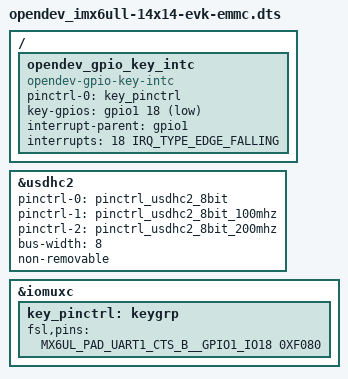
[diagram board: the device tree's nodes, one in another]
/*
 * Copyright 2019 NXP
 *
 * This program is free software; you can redistribute it and/or
 * modify it under the terms of the GNU General Public License
 * as published by the Free Software Foundation; either version 2
 * of the License, or (at your option) any later version.
 */

#include "imx6ull-14x14-evk.dts"

&usdhc2 {
	pinctrl-names = "default", "state_100mhz", "state_200mhz";
	pinctrl-0 = <&pinctrl_usdhc2_8bit>;
	pinctrl-1 = <&pinctrl_usdhc2_8bit_100mhz>;
	pinctrl-2 = <&pinctrl_usdhc2_8bit_200mhz>;
	bus-width = <8>;
	non-removable;
	status = "okay";
};

// &iomuxc {
// 	pinctrl_test: testgrp {
// 		fsl,pins = <
// 		MX6UL_PAD_GPIO1_IO00__GPIO1_IO00 config /* config 是具体设置的值 */
// 		>;
// 	};
// };

// 使用 pinctrl 和 GPIO 子系统的方式
&iomuxc {
    key_pinctrl: keygrp {
        fsl,pins = <
			MX6UL_PAD_UART1_CTS_B__GPIO1_IO18 0XF080 /* GPIO1_IO18 KEY0 */
        >;
    };
};

// 创建 GPIO 节点
/ {
    opendev_gpio_key_intc {
		#address-cells = <1>;
		#size-cells = <1>;
        compatible = "opendev-gpio-key-intc";
        pinctrl-names = "default";
		pinctrl-0 = <&key_pinctrl>;
		key-gpios = <&gpio1 18 GPIO_ACTIVE_LOW>; /* KEY0 */
		interrupt-parent = <&gpio1>;
		// define in include/dt-bindings/interrupt-controller/irq.h
		// interrupts = <18 IRQ_TYPE_LEVEL_LOW>
		interrupts = <18 IRQ_TYPE_EDGE_FALLING>;
		status = "okay";
	};
};
